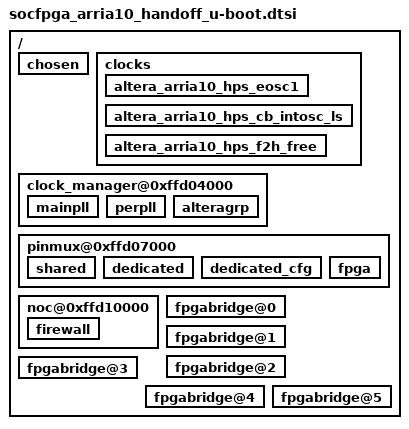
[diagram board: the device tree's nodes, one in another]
// SPDX-License-Identifier: GPL-2.0+ OR X11

/ {
	chosen {
		bootph-all;
	};

	clocks {
		bootph-all;

		altera_arria10_hps_eosc1 {
			bootph-all;
		};

		altera_arria10_hps_cb_intosc_ls {
			bootph-all;
		};

		altera_arria10_hps_f2h_free {
			bootph-all;
		};
	};

	clock_manager@0xffd04000 {
		bootph-all;

		mainpll {
			bootph-all;
		};

		perpll {
			bootph-all;
		};

		alteragrp {
			bootph-all;
		};
	};

	pinmux@0xffd07000 {
		bootph-all;

		shared {
			bootph-all;
		};

		dedicated {
			bootph-all;
		};

		dedicated_cfg {
			bootph-all;
		};

		fpga {
			bootph-all;
		};
	};

	noc@0xffd10000 {
		bootph-all;

		firewall {
			bootph-all;
		};
	};

	fpgabridge@0 {
		bootph-all;
	};

	fpgabridge@1 {
		bootph-all;
	};

	fpgabridge@2 {
		bootph-all;
	};

	fpgabridge@3 {
		bootph-all;
	};

	fpgabridge@4 {
		bootph-all;
	};

	fpgabridge@5 {
		bootph-all;
	};
};
